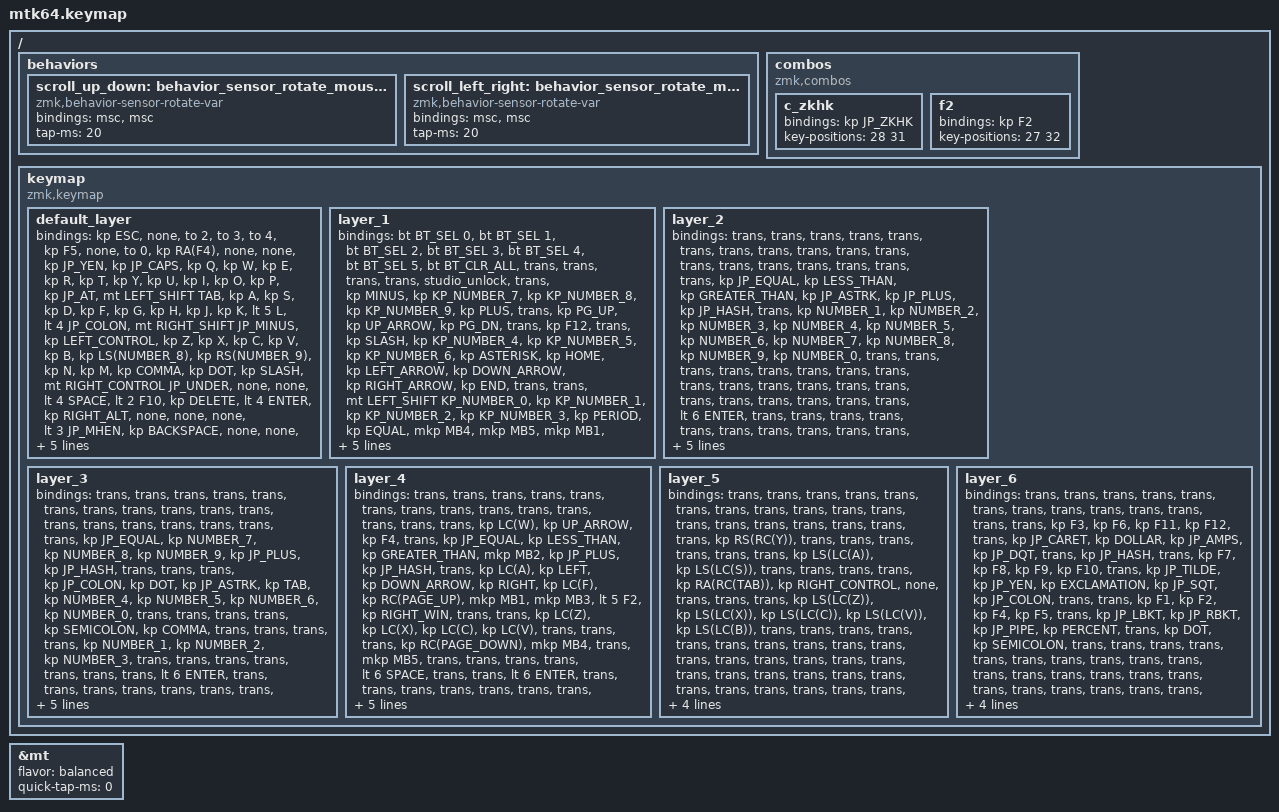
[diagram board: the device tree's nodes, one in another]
#include <input/processors.dtsi>
#include <behaviors.dtsi>
#include <dt-bindings/zmk/bt.h>
#include <dt-bindings/zmk/keys.h>
#include <dt-bindings/zmk/pointing.h>
#include "keycode_japanese.h"

// スクロール量の設定

#define ZMK_POINTING_DEFAULT_SCRL_VAL 100

&mt {
    flavor = "balanced";
    quick-tap-ms = <0>;
};

// &mkp_input_listener { input-processors = <&zip_temp_layer 6 5000>; };

/ {
    behaviors {
        // 垂直スクロール用のbehaviorの設定

        scroll_up_down: behavior_sensor_rotate_mouse_wheel_up_down {
            compatible = "zmk,behavior-sensor-rotate-var";
            #sensor-binding-cells = <2>;
            bindings = <&msc>, <&msc>;

            tap-ms = <20>; // スクロールのタップ時間
        };

        // 水平スクロール用のbehaviorの設定

        scroll_left_right: behavior_sensor_rotate_mouse_wheel_left_right {
            compatible = "zmk,behavior-sensor-rotate-var";
            #sensor-binding-cells = <2>;
            bindings = <&msc>, <&msc>;

            tap-ms = <20>; // スクロールのタップ時間
        };
    };
};

/ {
    combos {
        compatible = "zmk,combos";

        c_zkhk {
            bindings = <&kp JP_ZKHK>;
            key-positions = <28 31>;
        };

        f2 {
            bindings = <&kp F2>;
            key-positions = <27 32>;
        };
    };

    keymap {
        compatible = "zmk,keymap";

        default_layer {
            bindings = <
&kp ESC  &none  &to 2  &to 3  &to 4  &kp F5  &none  &to 0  &kp RA(F4)  &none  &none  &kp JP_YEN  &kp JP_CAPS  &kp Q  &kp W  &kp E  &kp R  &kp T  &kp Y  &kp U  &kp I  &kp O  &kp P  &kp JP_AT  &mt LEFT_SHIFT TAB  &kp A  &kp S  &kp D  &kp F  &kp G  &kp H  &kp J  &kp K  &lt 5 L  &lt 4 JP_COLON  &mt RIGHT_SHIFT JP_MINUS  &kp LEFT_CONTROL  &kp Z  &kp X  &kp C  &kp V  &kp B  &kp LS(NUMBER_8)  &kp RS(NUMBER_9)  &kp N  &kp M  &kp COMMA  &kp DOT  &kp SLASH  &mt RIGHT_CONTROL JP_UNDER  &none  &none  &lt 4 SPACE  &lt 2 F10  &kp DELETE  &lt 4 ENTER  &kp RIGHT_ALT  &none  &none  &none  &lt 3 JP_MHEN  &kp BACKSPACE  &none  &none  &kp JP_HENK  &kp RIGHT_WIN  &mo 1  &mo 2  &mo 3  &mo 1  &mo 2  &mo 3  &mo 1  &mo 2  &mo 3
            >;

            sensor-bindings = <
                &inc_dec_kp RIGHT_ARROW LEFT_ARROW
                &inc_dec_kp UP_ARROW   DOWN_ARROW
            >;
        };

        layer_1 {
            bindings = <
&bt BT_SEL 0  &bt BT_SEL 1  &bt BT_SEL 2  &bt BT_SEL 3  &bt BT_SEL 4  &bt BT_SEL 5  &bt BT_CLR_ALL  &trans  &trans  &trans  &trans  &studio_unlock  &trans  &kp MINUS  &kp KP_NUMBER_7  &kp KP_NUMBER_8  &kp KP_NUMBER_9  &kp PLUS  &trans  &kp PG_UP  &kp UP_ARROW  &kp PG_DN  &trans  &kp F12  &trans  &kp SLASH  &kp KP_NUMBER_4  &kp KP_NUMBER_5  &kp KP_NUMBER_6  &kp ASTERISK  &kp HOME  &kp LEFT_ARROW  &kp DOWN_ARROW  &kp RIGHT_ARROW  &kp END  &trans  &trans  &mt LEFT_SHIFT KP_NUMBER_0  &kp KP_NUMBER_1  &kp KP_NUMBER_2  &kp KP_NUMBER_3  &kp PERIOD  &kp EQUAL  &mkp MB4  &mkp MB5  &mkp MB1  &mkp MB2  &mkp MB3  &trans  &trans  &trans  &trans  &trans  &trans  &trans  &trans  &trans  &trans  &trans  &trans  &trans  &trans  &trans  &trans  &trans  &trans  &trans  &trans  &trans  &trans  &trans  &trans  &trans  &trans  &trans
            >;
        };

        layer_2 {
            bindings = <
&trans  &trans  &trans  &trans  &trans  &trans  &trans  &trans  &trans  &trans  &trans  &trans  &trans  &trans  &trans  &trans  &trans  &trans  &kp JP_EQUAL  &kp LESS_THAN  &kp GREATER_THAN  &kp JP_ASTRK  &kp JP_PLUS  &kp JP_HASH  &trans  &kp NUMBER_1  &kp NUMBER_2  &kp NUMBER_3  &kp NUMBER_4  &kp NUMBER_5  &kp NUMBER_6  &kp NUMBER_7  &kp NUMBER_8  &kp NUMBER_9  &kp NUMBER_0  &trans  &trans  &trans  &trans  &trans  &trans  &trans  &trans  &trans  &trans  &trans  &trans  &trans  &trans  &trans  &trans  &trans  &trans  &trans  &trans  &lt 6 ENTER  &trans  &trans  &trans  &trans  &trans  &trans  &trans  &trans  &trans  &trans  &trans  &trans  &trans  &trans  &trans  &trans  &trans  &trans  &trans
            >;

            sensor-bindings = <
                &inc_dec_kp RIGHT_ARROW LEFT_ARROW
                &inc_dec_kp UP_ARROW   DOWN_ARROW
            >;
        };

        layer_3 {
            bindings = <
&trans  &trans  &trans  &trans  &trans  &trans  &trans  &trans  &trans  &trans  &trans  &trans  &trans  &trans  &trans  &trans  &trans  &trans  &kp JP_EQUAL  &kp NUMBER_7  &kp NUMBER_8  &kp NUMBER_9  &kp JP_PLUS  &kp JP_HASH  &trans  &trans  &trans  &kp JP_COLON  &kp DOT  &kp JP_ASTRK  &kp TAB  &kp NUMBER_4  &kp NUMBER_5  &kp NUMBER_6  &kp NUMBER_0  &trans  &trans  &trans  &trans  &kp SEMICOLON  &kp COMMA  &trans  &trans  &trans  &trans  &kp NUMBER_1  &kp NUMBER_2  &kp NUMBER_3  &trans  &trans  &trans  &trans  &trans  &trans  &trans  &lt 6 ENTER  &trans  &trans  &trans  &trans  &trans  &trans  &trans  &trans  &trans  &trans  &trans  &trans  &trans  &trans  &trans  &trans  &trans  &trans  &trans
            >;

            sensor-bindings = <
                &inc_dec_kp RIGHT_ARROW LEFT_ARROW
                &inc_dec_kp UP_ARROW   DOWN_ARROW
            >;
        };

        layer_4 {
            bindings = <
&trans  &trans  &trans  &trans  &trans  &trans  &trans  &trans  &trans  &trans  &trans  &trans  &trans  &trans  &kp LC(W)  &kp UP_ARROW  &kp F4  &trans  &kp JP_EQUAL  &kp LESS_THAN  &kp GREATER_THAN  &mkp MB2  &kp JP_PLUS  &kp JP_HASH  &trans  &kp LC(A)  &kp LEFT  &kp DOWN_ARROW  &kp RIGHT  &kp LC(F)  &kp RC(PAGE_UP)  &mkp MB1  &mkp MB3  &lt 5 F2  &kp RIGHT_WIN  &trans  &trans  &kp LC(Z)  &kp LC(X)  &kp LC(C)  &kp LC(V)  &trans  &trans  &trans  &kp RC(PAGE_DOWN)  &mkp MB4  &trans  &mkp MB5  &trans  &trans  &trans  &trans  &lt 6 SPACE  &trans  &trans  &lt 6 ENTER  &trans  &trans  &trans  &trans  &trans  &trans  &trans  &trans  &trans  &trans  &trans  &trans  &trans  &trans  &trans  &trans  &trans  &trans  &trans
            >;

            sensor-bindings = <
                &inc_dec_kp RIGHT_ARROW LEFT_ARROW
                &inc_dec_kp UP_ARROW   DOWN_ARROW
            >;
        };

        layer_5 {
            bindings = <
&trans  &trans  &trans  &trans  &trans  &trans  &trans  &trans  &trans  &trans  &trans  &trans  &trans  &trans  &trans  &trans  &trans  &trans  &kp RS(RC(Y))  &trans  &trans  &trans  &trans  &trans  &trans  &kp LS(LC(A))  &kp LS(LC(S))  &trans  &trans  &trans  &trans  &kp RA(RC(TAB))  &kp RIGHT_CONTROL  &none  &trans  &trans  &trans  &kp LS(LC(Z))  &kp LS(LC(X))  &kp LS(LC(C))  &kp LS(LC(V))  &kp LS(LC(B))  &trans  &trans  &trans  &trans  &trans  &trans  &trans  &trans  &trans  &trans  &trans  &trans  &trans  &trans  &trans  &trans  &trans  &trans  &trans  &trans  &trans  &trans  &trans  &trans  &trans  &trans  &trans  &trans  &trans  &trans  &trans  &trans  &trans
            >;

            sensor-bindings =
                <&scroll_left_right SCRL_RIGHT SCRL_LEFT>,
                <&scroll_up_down SCRL_UP SCRL_DOWN>;
        };

        layer_6 {
            bindings = <
&trans  &trans  &trans  &trans  &trans  &trans  &trans  &trans  &trans  &trans  &trans  &trans  &trans  &kp F3  &kp F6  &kp F11  &kp F12  &trans  &kp JP_CARET  &kp DOLLAR  &kp JP_AMPS  &kp JP_DQT  &trans  &kp JP_HASH  &trans  &kp F7  &kp F8  &kp F9  &kp F10  &trans  &kp JP_TILDE  &kp JP_YEN  &kp EXCLAMATION  &kp JP_SQT  &kp JP_COLON  &trans  &trans  &kp F1  &kp F2  &kp F4  &kp F5  &trans  &kp JP_LBKT  &kp JP_RBKT  &kp JP_PIPE  &kp PERCENT  &trans  &kp DOT  &kp SEMICOLON  &trans  &trans  &trans  &trans  &trans  &trans  &trans  &trans  &trans  &trans  &trans  &trans  &trans  &trans  &trans  &trans  &trans  &trans  &trans  &trans  &trans  &trans  &trans  &trans  &trans  &trans
            >;

            sensor-bindings = <
                &inc_dec_kp RIGHT_ARROW LEFT_ARROW
                &inc_dec_kp UP_ARROW   DOWN_ARROW
            >;
        };
    };
};
